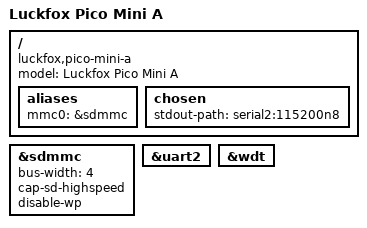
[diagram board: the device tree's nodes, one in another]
// SPDX-License-Identifier: (GPL-2.0+ OR MIT)
/*
 * Copyright (c) 2023 Luckfox Electronics Co., Ltd
 */

/dts-v1/;

#include "rv1103.dtsi"

/ {
	model = "Luckfox Pico Mini A";
	compatible = "luckfox,pico-mini-a", "rockchip,rv1103";

	aliases {
		mmc0 = &sdmmc;
	};

	chosen {
		stdout-path = "serial2:115200n8";
	};
};

&sdmmc {
	bus-width = <4>;
	cap-sd-highspeed;
	disable-wp;
	status = "okay";
};

&uart2 {
	bootph-all;
	status = "okay";
};

&wdt {
	status = "okay";
};
